VERSION ""

NS_ :

BS_:

BU_: DiagEcu MainEcu EngineEcu FrontEcu RearEcu
VAL_TABLE_ VT_EngineConditions 2 "Fault" 1 "EngineRunning" 0 "EngineStopped" ;
VAL_TABLE_ VT_LightSignals 2 "Error" 1 "LightOn" 0 "LightOff" ;
VAL_TABLE_ VT_DoorSignals 2 "Error" 1 "DoorUnlocked" 0 "DoorLocked" ;

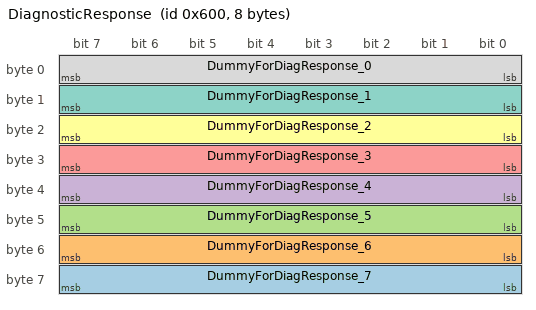
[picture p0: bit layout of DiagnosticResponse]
BO_ 1536 DiagnosticResponse: 8 Vector__XXX
 SG_ DummyForDiagResponse_7 : 56|8@1+ (1,0) [0|255] ""  DiagEcu
 SG_ DummyForDiagResponse_6 : 48|8@1+ (1,0) [0|255] ""  DiagEcu
 SG_ DummyForDiagResponse_5 : 40|8@1+ (1,0) [0|255] ""  DiagEcu
 SG_ DummyForDiagResponse_4 : 32|8@1+ (1,0) [0|255] ""  DiagEcu
 SG_ DummyForDiagResponse_3 : 24|8@1+ (1,0) [0|255] ""  DiagEcu
 SG_ DummyForDiagResponse_2 : 16|8@1+ (1,0) [0|255] ""  DiagEcu
 SG_ DummyForDiagResponse_1 : 8|8@1+ (1,0) [0|255] ""  DiagEcu
 SG_ DummyForDiagResponse_0 : 0|8@1+ (1,0) [0|255] ""  DiagEcu

BO_ 1792 DiagnosticResquest: 8 DiagEcu

BO_ 20 Rear_LightStatus: 8 RearEcu
 SG_ Sig_R_LightStatus : 0|8@1+ (1,0) [0|0] ""  MainEcu

BO_ 19 Front_LightStatus: 8 FrontEcu
 SG_ Sig_F_LightStatus : 0|8@1+ (1,0) [0|0] ""  MainEcu

BO_ 18 Rear_DoorStatus: 8 RearEcu
 SG_ Sig_RR_Door_Status : 0|8@1+ (1,0) [0|0] ""  MainEcu
 SG_ Sig_RL_Door_Status : 8|8@1+ (1,0) [0|0] ""  MainEcu

BO_ 17 Front_DoorStatus: 8 FrontEcu
 SG_ Sig_FR_Door_Status : 0|8@1+ (1,0) [0|0] ""  MainEcu
 SG_ Sig_FL_Door_Status : 8|8@1+ (1,0) [0|0] ""  MainEcu

BO_ 16 EngineStatus: 8 EngineEcu
 SG_ Sig_EngineStatus : 0|8@1+ (1,0) [0|0] ""  MainEcu

BO_ 3 Rear_LightControl: 8 MainEcu
 SG_ Sig_R_light_Control : 0|8@1+ (1,0) [0|0] ""  RearEcu

BO_ 2 Engine_SpeedControl: 8 MainEcu
 SG_ Sig_SpeedControl : 0|8@1+ (1,0) [0|180] "km/h"  EngineEcu

BO_ 1 Front_LightControl: 8 MainEcu
 SG_ Sig_F_light_Control : 0|8@1+ (1,0) [0|0] ""  FrontEcu

CM_ BO_ 20 "Cyclic message handles Rear light status";
CM_ SG_ 20 Sig_R_LightStatus "Signal to handle the Rear light status";
CM_ BO_ 19 "Cyclic message handles Front light Status";
CM_ SG_ 19 Sig_F_LightStatus "Signal to handle the front light status";
CM_ BO_ 18 "Cyclic message handles Rear Doors Status ";
CM_ SG_ 18 Sig_RR_Door_Status "Signal to handle the Rear right Door status ";
CM_ SG_ 18 Sig_RL_Door_Status "Signal to handle the Rear left Door status ";
CM_ BO_ 17 "Cyclic message handles Front Doors Status";
CM_ SG_ 17 Sig_FR_Door_Status "Signal to handle the front right Door status ";
CM_ SG_ 17 Sig_FL_Door_Status "Signal to handle the front left Door status ";
CM_ BO_ 16 "Cyclic message handles Engine Status";
CM_ SG_ 16 Sig_EngineStatus "Signal to handle the Engine Status";
CM_ BO_ 3 "Triggered message Control Rear light Status";
CM_ SG_ 3 Sig_R_light_Control "Light control signal from the main ECU";
CM_ BO_ 2 "Triggered message Control Engine Speed.";
CM_ SG_ 2 Sig_SpeedControl "Speed control signal from the main ECU";
CM_ BO_ 1 "Triggered message Control Front light Status";
CM_ SG_ 1 Sig_F_light_Control "Light control signal from the main ECU";
BA_DEF_ BO_  "GenMsgSendType" ENUM  "Cyclic","OnTrigger","Cyclic_OnTrigger";
BA_DEF_  "BoudRate" INT 50000 100000;
BA_DEF_ BO_  "GenMsgCycleTime" INT 0 1000;
BA_DEF_  "BusType" STRING ;
BA_DEF_DEF_  "GenMsgSendType" "OnTrigger";
BA_DEF_DEF_  "BoudRate" 50000;
BA_DEF_DEF_  "GenMsgCycleTime" 0;
BA_DEF_DEF_  "BusType" "CAN";
BA_ "GenMsgCycleTime" BO_ 20 100;
BA_ "GenMsgSendType" BO_ 20 0;
BA_ "GenMsgCycleTime" BO_ 19 100;
BA_ "GenMsgSendType" BO_ 19 0;
BA_ "GenMsgCycleTime" BO_ 18 40;
BA_ "GenMsgSendType" BO_ 18 0;
BA_ "GenMsgCycleTime" BO_ 17 40;
BA_ "GenMsgSendType" BO_ 17 0;
BA_ "GenMsgCycleTime" BO_ 16 10;
BA_ "GenMsgSendType" BO_ 16 0;
VAL_ 20 Sig_R_LightStatus 2 "Error" 1 "LightOn" 0 "LightOff" ;
VAL_ 19 Sig_F_LightStatus 2 "Error" 1 "LightOn" 0 "LightOff" ;
VAL_ 18 Sig_RR_Door_Status 2 "Error" 1 "DoorUnlocked" 0 "DoorLocked" ;
VAL_ 18 Sig_RL_Door_Status 2 "Error" 1 "DoorUnlocked" 0 "DoorLocked" ;
VAL_ 17 Sig_FR_Door_Status 2 "Error" 1 "DoorUnlocked" 0 "DoorLocked" ;
VAL_ 17 Sig_FL_Door_Status 2 "Error" 1 "DoorUnlocked" 0 "DoorLocked" ;
VAL_ 16 Sig_EngineStatus 2 "Fault" 1 "EngineRunning" 0 "EngineStopped" ;
VAL_ 3 Sig_R_light_Control 2 "Error" 1 "LightOn" 0 "LightOff" ;
VAL_ 1 Sig_F_light_Control 2 "Error" 1 "LightOn" 0 "LightOff" ;
